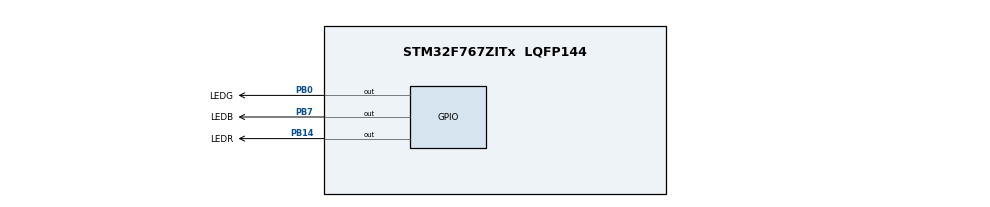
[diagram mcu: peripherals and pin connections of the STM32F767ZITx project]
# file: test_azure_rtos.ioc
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Mcu.Family=STM32F7
Mcu.Name=STM32F767ZITx
Mcu.Package=LQFP144
Mcu.UserConstants=MEMORY_POOL_TOTAL_SIZE,2048;TRACEX_BUFFER_SIZE,64000
NVIC.PriorityGroup=NVIC_PRIORITYGROUP_4
NVIC.TIM6_DAC_IRQn=true\:15\:0\:false\:false\:true\:false\:false\:true\:true
NVIC.TimeBase=TIM6_DAC_IRQn
NVIC.TimeBaseIP=TIM6
PB0.GPIO_Label=LEDG
PB0.Signal=GPIO_Output
PB14.GPIO_Label=LEDR
PB14.Signal=GPIO_Output
PB7.GPIO_Label=LEDB
PB7.Signal=GPIO_Output
ProjectManager.HeapSize=0x200
ProjectManager.StackSize=0x400
ProjectManager.TargetToolchain=STM32CubeIDE
RCC.HSE_VALUE=25000000
RCC.HSI_VALUE=16000000
RCC.LSE_VALUE=32768
RCC.USBFreq_Value=96000000
RCC.VCOOutputFreq_Value=192000000
STMicroelectronics.X-CUBE-AZRTOS-F7.1.1.0.TX_APP_MEM_POOL_SIZE=MEMORY_POOL_TOTAL_SIZE
STMicroelectronics.X-CUBE-AZRTOS-F7.1.1.0.TX_BASEPRI_SUPPORT=0
STMicroelectronics.X-CUBE-AZRTOS-F7.1.1.0.TX_ENABLE_EVENT_TRACE=1
STMicroelectronics.X-CUBE-AZRTOS-F7.1.1.0.TX_TIMER_PROCESS_IN_ISR=0
STMicroelectronics.X-CUBE-AZRTOS-F7.1.1.0.ThreadXCcRTOSJjThreadXJjCore=true
STMicroelectronics.X-CUBE-AZRTOS-F7.1.1.0.ThreadXCcRTOSJjThreadXJjLowOoPowerOosupport=true
STMicroelectronics.X-CUBE-AZRTOS-F7.1.1.0.ThreadXCcRTOSJjThreadXJjPerformanceInfo=true
STMicroelectronics.X-CUBE-AZRTOS-F7.1.1.0.ThreadXCcRTOSJjThreadXJjTraceXOosupport=true
STMicroelectronics.X-CUBE-AZRTOS-F7.1.1.0_IsAnAzureRtosMw=true
VP_STMicroelectronics.X-CUBE-AZRTOS-F7_VS_RTOSJjThreadX_6.1.10_1.1.0.Mode=RTOSJjThreadX
VP_SYS_VS_tim6.Mode=TIM6
VP_TIM7_VS_ClockSourceINT.Mode=Enable_Timer
board=custom

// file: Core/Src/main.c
/* USER CODE BEGIN Header */
/**
  ******************************************************************************
  * @file           : main.c
  * @brief          : Main program body
  ******************************************************************************
  * @attention
  *
  * Copyright (c) 2023 STMicroelectronics.
  * All rights reserved.
  *
  * This software is licensed under terms that can be found in the LICENSE file
  * in the root directory of this software component.
  * If no LICENSE file comes with this software, it is provided AS-IS.
  *
  ******************************************************************************
  */
/* USER CODE END Header */
#include "app_threadx.h"
#include "main.h"

TIM_HandleTypeDef htim7;

/* Timtick space
/*
 * Copy of uwTicks
 * Stored on a fixed address
 *
 */
uint32_t timtick __attribute__ ((section(".timtickspace")));

void SystemClock_Config(void);
static void MX_GPIO_Init(void);
static void MX_TIM7_Init(void);

/* USER CODE BEGIN PFP */

void HAL_IncTick(void);
/* USER CODE END PFP */

int main(void)
{

  /* MCU Configuration--------------------------------------------------------*/

  /* Reset of all peripherals, Initializes the Flash interface and the Systick. */
  HAL_Init();

  /* Configure the system clock */
  SystemClock_Config();

  /* Initialize all configured peripherals */
  MX_GPIO_Init();
  MX_TIM7_Init();

  MX_ThreadX_Init();

  /* We should never get here as control is now taken by the scheduler */
  /* Infinite loop */
  while (1)
  {

  }
}

void SystemClock_Config(void)
{
  RCC_OscInitTypeDef RCC_OscInitStruct = {0};
  RCC_ClkInitTypeDef RCC_ClkInitStruct = {0};

  /** Configure the main internal regulator output voltage
  */
  __HAL_RCC_PWR_CLK_ENABLE();
  __HAL_PWR_VOLTAGESCALING_CONFIG(PWR_REGULATOR_VOLTAGE_SCALE3);

  /** Initializes the RCC Oscillators according to the specified parameters
  * in the RCC_OscInitTypeDef structure.
  */
  RCC_OscInitStruct.OscillatorType = RCC_OSCILLATORTYPE_HSI;
  RCC_OscInitStruct.HSIState = RCC_HSI_ON;
  RCC_OscInitStruct.HSICalibrationValue = RCC_HSICALIBRATION_DEFAULT;
  RCC_OscInitStruct.PLL.PLLState = RCC_PLL_NONE;
  if (HAL_RCC_OscConfig(&RCC_OscInitStruct) != HAL_OK)
  {
    Error_Handler();
  }

  /** Initializes the CPU, AHB and APB buses clocks
  */
  RCC_ClkInitStruct.ClockType = RCC_CLOCKTYPE_HCLK|RCC_CLOCKTYPE_SYSCLK
                              |RCC_CLOCKTYPE_PCLK1|RCC_CLOCKTYPE_PCLK2;
  RCC_ClkInitStruct.SYSCLKSource = RCC_SYSCLKSOURCE_HSI;
  RCC_ClkInitStruct.AHBCLKDivider = RCC_SYSCLK_DIV1;
  RCC_ClkInitStruct.APB1CLKDivider = RCC_HCLK_DIV1;
  RCC_ClkInitStruct.APB2CLKDivider = RCC_HCLK_DIV1;

  if (HAL_RCC_ClockConfig(&RCC_ClkInitStruct, FLASH_LATENCY_0) != HAL_OK)
  {
    Error_Handler();
  }
}

static void MX_TIM7_Init(void)
{

  TIM_MasterConfigTypeDef sMasterConfig = {0};

  htim7.Instance = TIM7;
  htim7.Init.Prescaler = 0;
  htim7.Init.CounterMode = TIM_COUNTERMODE_UP;
  htim7.Init.Period = 65535;
  htim7.Init.AutoReloadPreload = TIM_AUTORELOAD_PRELOAD_DISABLE;
  if (HAL_TIM_Base_Init(&htim7) != HAL_OK)
  {
    Error_Handler();
  }
  sMasterConfig.MasterOutputTrigger = TIM_TRGO_RESET;
  sMasterConfig.MasterSlaveMode = TIM_MASTERSLAVEMODE_DISABLE;
  if (HAL_TIMEx_MasterConfigSynchronization(&htim7, &sMasterConfig) != HAL_OK)
  {
    Error_Handler();
  }

}

static void MX_GPIO_Init(void)
{
  GPIO_InitTypeDef GPIO_InitStruct = {0};

  /* GPIO Ports Clock Enable */
  __HAL_RCC_GPIOB_CLK_ENABLE();

  /*Configure GPIO pin Output Level */
  HAL_GPIO_WritePin(GPIOB, LEDG_Pin|LEDR_Pin|LEDB_Pin, GPIO_PIN_RESET);

  /*Configure GPIO pins : LEDG_Pin LEDR_Pin LEDB_Pin */
  GPIO_InitStruct.Pin = LEDG_Pin|LEDR_Pin|LEDB_Pin;
  GPIO_InitStruct.Mode = GPIO_MODE_OUTPUT_PP;
  GPIO_InitStruct.Pull = GPIO_NOPULL;
  GPIO_InitStruct.Speed = GPIO_SPEED_FREQ_LOW;
  HAL_GPIO_Init(GPIOB, &GPIO_InitStruct);

}

/* USER CODE BEGIN 4 */

void HAL_IncTick(void) {
	uwTick += uwTickFreq;
	timtick = uwTick;
}
/* USER CODE END 4 */

void HAL_TIM_PeriodElapsedCallback(TIM_HandleTypeDef *htim)
{
  if (htim->Instance == TIM6) {
    HAL_IncTick();
  }
}

void Error_Handler(void)
{
  __disable_irq();
  while (1)
  {
  }
}
